AUTOSAR XML (schema 4-2-2)
package /AUTOSAR_BswM/SwComponentTypes
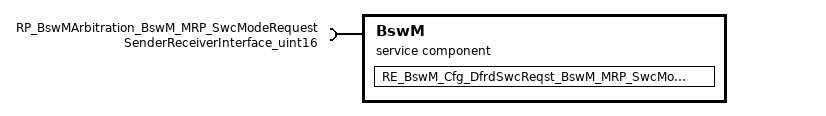
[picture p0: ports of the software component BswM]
  service sw component type BswM
    require port RP_BswMArbitration_BswM_MRP_SwcModeRequest: required-interface=SenderReceiverInterface_uint16
    behavior IB_BswM: data-type-mapping=ECUM_STATE_Mapping
      data received event DRE_BswM_Cfg_DfrdSwcReqst_BswM_MRP_SwcModeRequest: start-on-event=RE_BswM_Cfg_DfrdSwcReqst_BswM_MRP_SwcModeRequest, data=RP_BswMArbitration_BswM_MRP_SwcModeRequest.VDP_uint16
      runnable RE_BswM_Cfg_DfrdSwcReqst_BswM_MRP_SwcModeRequest: can-be-invoked-concurrently=true, symbol=BswM_Cfg_DfrdSwcReqst_BswM_MRP_SwcModeRequest
        data-receive-point-by-arguments:
          access DRP_BswM_MRP_SwcModeRequest: accessed-variable=RP_BswMArbitration_BswM_MRP_SwcModeRequest.VDP_uint16
package /AUTOSAR_BswM/ImplementationDataTypes
  impl type BswM_ModeType: implementation-data-type=uint16
  impl type BswM_UserType: implementation-data-type=uint16
package /AUTOSAR_BswM/SwcImplementations
  swc implementation SWCIMPL_BswM: programming-language=C, sw-version=1.0.0, behavior=IB_BswM
    code-descriptors:
      code CodeDescriptor: artifact-descriptors=autosar-engineering-object={short-label=ArEngObj, category=SWSRC}
